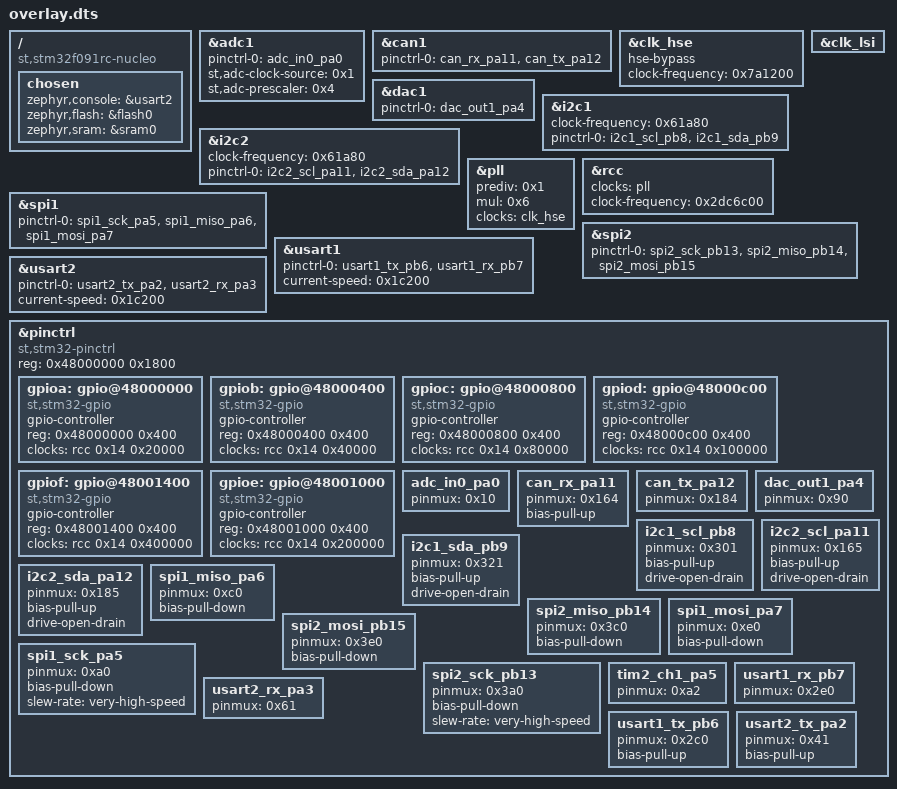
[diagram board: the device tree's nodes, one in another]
/ {
	compatible = "st,stm32f091rc-nucleo";
	chosen {
		zephyr,console = &usart2;
		zephyr,flash = &flash0;
		zephyr,sram = &sram0;
	};
};
&adc1{
	status = "okay";
	pinctrl-0 = < &adc_in0_pa0 >;
	pinctrl-names = "default";
	st,adc-clock-source = < 0x1 >;
	st,adc-prescaler = < 0x4 >;
};
&can1{
	status = "okay";
	pinctrl-0 = < &can_rx_pa11 &can_tx_pa12 >;
	pinctrl-names = "default";
};
&clk_hse{
	status = "okay";
	hse-bypass;
	clock-frequency = < 0x7a1200 >;
};
&clk_lsi{
	status = "okay";
};
&dac1{
	status = "okay";
	pinctrl-0 = < &dac_out1_pa4 >;
	pinctrl-names = "default";
};
&i2c1{
	clock-frequency = < 0x61a80 >;
	status = "okay";
	pinctrl-0 = < &i2c1_scl_pb8 &i2c1_sda_pb9 >;
	pinctrl-names = "default";
};
&i2c2{
	clock-frequency = < 0x61a80 >;
	pinctrl-0 = < &i2c2_scl_pa11 &i2c2_sda_pa12 >;
	pinctrl-names = "default";
};
&pll{
	status = "okay";
	prediv = < 0x1 >;
	mul = < 0x6 >;
	clocks = < &clk_hse >;
};
&rcc{
	clocks = < &pll >;
	clock-frequency = < 0x2dc6c00 >;
};
&spi1{
	status = "okay";
	pinctrl-0 = < &spi1_sck_pa5 &spi1_miso_pa6 &spi1_mosi_pa7 >;
	pinctrl-names = "default";
};
&spi2{
	status = "okay";
	pinctrl-0 = < &spi2_sck_pb13 &spi2_miso_pb14 &spi2_mosi_pb15 >;
	pinctrl-names = "default";
};
&usart1{
	pinctrl-0 = < &usart1_tx_pb6 &usart1_rx_pb7 >;
	pinctrl-names = "default";
	current-speed = < 0x1c200 >;
};
&usart2{
	status = "okay";
	pinctrl-0 = < &usart2_tx_pa2 &usart2_rx_pa3 >;
	pinctrl-names = "default";
	current-speed = < 0x1c200 >;
};
&pinctrl{
	compatible = "st,stm32-pinctrl";
	#address-cells = < 0x1 >;
	#size-cells = < 0x1 >;
	reg = < 0x48000000 0x1800 >;
	gpioa: gpio@48000000 {
		compatible = "st,stm32-gpio";
		gpio-controller;
		#gpio-cells = < 0x2 >;
		reg = < 0x48000000 0x400 >;
		clocks = < &rcc 0x14 0x20000 >;
	};
	gpiob: gpio@48000400 {
		compatible = "st,stm32-gpio";
		gpio-controller;
		#gpio-cells = < 0x2 >;
		reg = < 0x48000400 0x400 >;
		clocks = < &rcc 0x14 0x40000 >;
	};
	gpioc: gpio@48000800 {
		compatible = "st,stm32-gpio";
		gpio-controller;
		#gpio-cells = < 0x2 >;
		reg = < 0x48000800 0x400 >;
		clocks = < &rcc 0x14 0x80000 >;
	};
	gpiod: gpio@48000c00 {
		compatible = "st,stm32-gpio";
		gpio-controller;
		#gpio-cells = < 0x2 >;
		reg = < 0x48000c00 0x400 >;
		clocks = < &rcc 0x14 0x100000 >;
	};
	gpiof: gpio@48001400 {
		compatible = "st,stm32-gpio";
		gpio-controller;
		#gpio-cells = < 0x2 >;
		reg = < 0x48001400 0x400 >;
		clocks = < &rcc 0x14 0x400000 >;
	};
	gpioe: gpio@48001000 {
		compatible = "st,stm32-gpio";
		gpio-controller;
		#gpio-cells = < 0x2 >;
		reg = < 0x48001000 0x400 >;
		clocks = < &rcc 0x14 0x200000 >;
	};
	adc_in0_pa0: adc_in0_pa0 {
		pinmux = < 0x10 >;
	};
	can_rx_pa11: can_rx_pa11 {
		pinmux = < 0x164 >;
		bias-pull-up;
	};
	can_tx_pa12: can_tx_pa12 {
		pinmux = < 0x184 >;
	};
	dac_out1_pa4: dac_out1_pa4 {
		pinmux = < 0x90 >;
	};
	i2c1_scl_pb8: i2c1_scl_pb8 {
		pinmux = < 0x301 >;
		bias-pull-up;
		drive-open-drain;
	};
	i2c2_scl_pa11: i2c2_scl_pa11 {
		pinmux = < 0x165 >;
		bias-pull-up;
		drive-open-drain;
	};
	i2c1_sda_pb9: i2c1_sda_pb9 {
		pinmux = < 0x321 >;
		bias-pull-up;
		drive-open-drain;
	};
	i2c2_sda_pa12: i2c2_sda_pa12 {
		pinmux = < 0x185 >;
		bias-pull-up;
		drive-open-drain;
	};
	spi1_miso_pa6: spi1_miso_pa6 {
		pinmux = < 0xc0 >;
		bias-pull-down;
	};
	spi2_miso_pb14: spi2_miso_pb14 {
		pinmux = < 0x3c0 >;
		bias-pull-down;
	};
	spi1_mosi_pa7: spi1_mosi_pa7 {
		pinmux = < 0xe0 >;
		bias-pull-down;
	};
	spi2_mosi_pb15: spi2_mosi_pb15 {
		pinmux = < 0x3e0 >;
		bias-pull-down;
	};
	spi1_sck_pa5: spi1_sck_pa5 {
		pinmux = < 0xa0 >;
		bias-pull-down;
		slew-rate = "very-high-speed";
	};
	spi2_sck_pb13: spi2_sck_pb13 {
		pinmux = < 0x3a0 >;
		bias-pull-down;
		slew-rate = "very-high-speed";
	};
	tim2_ch1_pa5: tim2_ch1_pa5 {
		pinmux = < 0xa2 >;
	};
	usart1_rx_pb7: usart1_rx_pb7 {
		pinmux = < 0x2e0 >;
	};
	usart2_rx_pa3: usart2_rx_pa3 {
		pinmux = < 0x61 >;
	};
	usart1_tx_pb6: usart1_tx_pb6 {
		pinmux = < 0x2c0 >;
		bias-pull-up;
	};
	usart2_tx_pa2: usart2_tx_pa2 {
		pinmux = < 0x41 >;
		bias-pull-up;
	};
};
